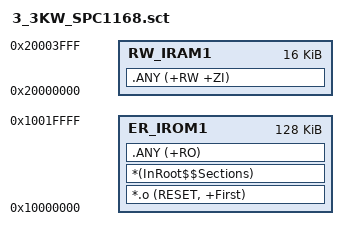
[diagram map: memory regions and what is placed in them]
; *************************************************************
; *** Scatter-Loading Description File generated by uVision ***
; *************************************************************
/*
LR_IROM1 0x00000000 0x00080000  {    ; load region size_region
  ER_IROM1 0x00000000 0x00080000  {  ; load address = execution address
   *.o (RESET, +First)
   *(InRoot$$Sections)
   .ANY (+RO)
  }
  RW_IRAM1 0x20000000 0x00020000  {  ; RW data
   .ANY (+RW +ZI)
  }
}
LR_IROM2 0x10008000 0x00004000 { ; load region size_region
ER_IROM2 0x1FFF8000 0x00004000 { ; load address = execution address
flash.o (+RO +RW +ZI)
}
}
*/


LR_IROM1 0x10000000 0x00020000  {    ; load region size_region
  ER_IROM1 0x10000000 0x00020000  {  ; load address = execution address
   *.o (RESET, +First)
   *(InRoot$$Sections)
   .ANY (+RO)
  }
  RW_IRAM1 0x20000000 0x00004000  {  ; RW data
   .ANY (+RW +ZI)
  }
}
